# f2838x_cm_csfr_regs register map
Vendor: Texas Instruments
Peripheral module from a debugger description file (folder C2000).
Address unit: 16 bits
Registers are 8-bit, read-write, no defined reset value unless marked. A register's access mark holds for its fields unless they carry their own. Offsets are as the file gives them; lines under a group give offsets from that group; [hi:lo] are bit positions; {n}, {i} and the like mark numbered series; 'fields as' and 'values as' point back to an identical list; <NAME> marks a mode.

## CSFR — CSFR Registers
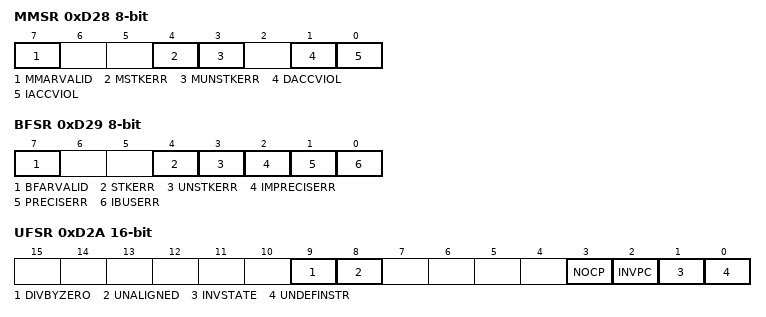
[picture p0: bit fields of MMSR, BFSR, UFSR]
0xD28 MMSR — MemManage Fault Status Register
  [7] MMARVALID — MemManage Fault Address Register (MMFAR) valid flag
  [4] MSTKERR — MemManage fault on stacking for exception entry
  [3] MUNSTKERR — MemManage fault on unstacking for a return from exception
  [1] DACCVIOL — Data access violation flag
  [0] IACCVIOL — Instruction access violation flag
0xD29 BFSR — BusFault Status Register
  [7] BFARVALID — BusFault Address Register (BFAR) valid flag
  [4] STKERR — BusFault on stacking for exception entry
  [3] UNSTKERR — BusFault on unstacking for a return from exception
  [2] IMPRECISERR — Imprecise data bus error
  [1] PRECISERR — Precise data bus error
  [0] IBUSERR — Instruction bus error
0xD2A UFSR 16-bit — UsageFault Status Register
  [9] DIVBYZERO — Divide by zero UsageFault
  [8] UNALIGNED — Unaligned access UsageFault
  [3] NOCP — No coprocessor UsageFault
  [2] INVPC — Invalid PC load UsageFault
  [1] INVSTATE — Invalid state UsageFault
  [0] UNDEFINSTR — Undefined instruction UsageFault
